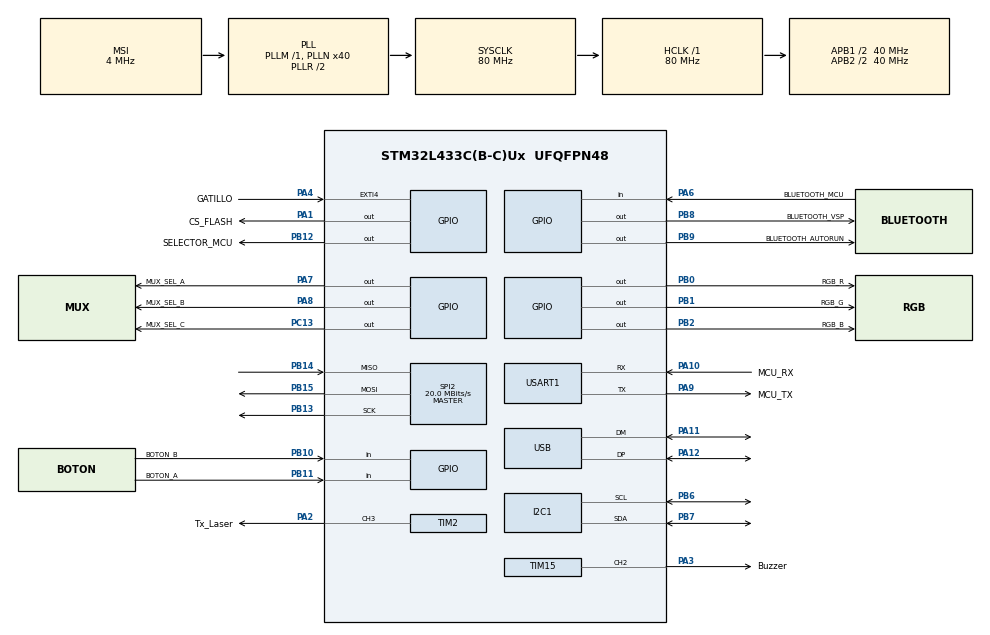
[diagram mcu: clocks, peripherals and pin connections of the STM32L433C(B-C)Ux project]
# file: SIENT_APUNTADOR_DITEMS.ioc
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FREERTOS.Tasks01=defaultTask,24,128,StartDefaultTask,Default,NULL,Dynamic,NULL,NULL
FREERTOS.configTOTAL_HEAP_SIZE=16384
FREERTOS.configUSE_NEWLIB_REENTRANT=1
FREERTOS.copyHeapFile=1
I2C1.CustomTiming=Disabled
I2C1.Timing=0x00D09BE3
Mcu.Family=STM32L4
Mcu.Name=STM32L433C(B-C)Ux
Mcu.Package=UFQFPN48
NVIC.EXTI4_IRQn=true\:5\:0\:false\:false\:true\:false\:true\:true\:true
NVIC.PriorityGroup=NVIC_PRIORITYGROUP_4
NVIC.TIM6_DAC_IRQn=true\:15\:0\:false\:false\:true\:false\:false\:true\:true
NVIC.TimeBase=TIM6_DAC_IRQn
NVIC.TimeBaseIP=TIM6
NVIC.USART1_IRQn=true\:5\:0\:true\:false\:true\:true\:true\:true\:true
NVIC.USB_IRQn=true\:5\:0\:false\:false\:true\:true\:false\:true\:true
PA1.GPIO_Label=CS_FLASH
PA1.Signal=GPIO_Output
PA10.GPIO_Label=MCU_RX
PA10.Mode=Asynchronous
PA10.Signal=USART1_RX
PA11.Mode=Device
PA11.Signal=USB_DM
PA12.Mode=Device
PA12.Signal=USB_DP
PA13\ (JTMS-SWDIO).Mode=Serial_Wire
PA13\ (JTMS-SWDIO).Signal=SYS_JTMS-SWDIO
PA14\ (JTCK-SWCLK).Mode=Serial_Wire
PA14\ (JTCK-SWCLK).Signal=SYS_JTCK-SWCLK
PA2.GPIO_Label=Tx_Laser
PA2.Signal=S_TIM2_CH3
PA3.GPIO_Label=Buzzer
PA3.Signal=S_TIM15_CH2
PA4.GPIO_Label=GATILLO
PA4.Signal=GPXTI4
PA6.GPIO_Label=BLUETOOTH_MCU
PA6.Signal=GPIO_Input
PA7.GPIO_Label=MUX_SEL_A
PA7.Signal=GPIO_Output
PA8.GPIO_Label=MUX_SEL_B
PA8.Signal=GPIO_Output
PA9.GPIO_Label=MCU_TX
PA9.Mode=Asynchronous
PA9.Signal=USART1_TX
PB0.GPIO_Label=RGB_R
PB0.Signal=GPIO_Output
PB1.GPIO_Label=RGB_G
PB1.Signal=GPIO_Output
PB10.GPIO_Label=BOTON_B
PB10.Signal=GPIO_Input
PB11.GPIO_Label=BOTON_A
PB11.Signal=GPIO_Input
PB12.GPIO_Label=SELECTOR_MCU
PB12.Signal=GPIO_Output
PB13.Mode=Full_Duplex_Master
PB13.Signal=SPI2_SCK
PB14.Mode=Full_Duplex_Master
PB14.Signal=SPI2_MISO
PB15.Mode=Full_Duplex_Master
PB15.Signal=SPI2_MOSI
PB2.GPIO_Label=RGB_B
PB2.Signal=GPIO_Output
PB6.Mode=I2C
PB6.Signal=I2C1_SCL
PB7.Mode=I2C
PB7.Signal=I2C1_SDA
PB8.GPIO_Label=BLUETOOTH_VSP
PB8.Signal=GPIO_Output
PB9.GPIO_Label=BLUETOOTH_AUTORUN
PB9.Signal=GPIO_Output
PC13.GPIO_Label=MUX_SEL_C
PC13.Signal=GPIO_Output
PC14-OSC32_IN\ (PC14).Mode=LSE-External-Oscillator
PC14-OSC32_IN\ (PC14).Signal=RCC_OSC32_IN
PC15-OSC32_OUT\ (PC15).Mode=LSE-External-Oscillator
PC15-OSC32_OUT\ (PC15).Signal=RCC_OSC32_OUT
ProjectManager.HeapSize=0x200
ProjectManager.StackSize=0x400
ProjectManager.TargetToolchain=STM32CubeIDE
RCC.ADCFreq_Value=48000000
RCC.AHBFreq_Value=80000000
RCC.APB1CLKDivider=RCC_HCLK_DIV2
RCC.APB1Freq_Value=40000000
RCC.APB1TimFreq_Value=80000000
RCC.APB2CLKDivider=RCC_HCLK_DIV2
RCC.APB2Freq_Value=40000000
RCC.APB2TimFreq_Value=80000000
RCC.CortexFreq_Value=80000000
RCC.HCLKFreq_Value=80000000
RCC.HSE_VALUE=8000000
RCC.HSI48_VALUE=48000000
RCC.HSI_VALUE=16000000
RCC.MSI_VALUE=4000000
RCC.PLLN=40
RCC.PLLSAI1N=24
RCC.SYSCLKFreq_VALUE=80000000
RCC.SYSCLKSource=RCC_SYSCLKSOURCE_PLLCLK
RCC.USBFreq_Value=48000000
RCC.VCOOutputFreq_Value=160000000
SH.S_TIM15_CH2.0=TIM15_CH2,PWM Generation2 CH2
SH.S_TIM2_CH3.0=TIM2_CH3,PWM Generation3 CH3
SPI2.CalculateBaudRate=20.0 MBits/s
SPI2.DataSize=SPI_DATASIZE_8BIT
SPI2.Direction=SPI_DIRECTION_2LINES
SPI2.Mode=SPI_MODE_MASTER
SPI2.VirtualType=VM_MASTER
TIM1.Prescaler=79
TIM15.Channel-PWM\ Generation2\ CH2=TIM_CHANNEL_2
TIM15.Prescaler=79
TIM2.Channel-PWM\ Generation3\ CH3=TIM_CHANNEL_3
TIM2.Period=24
TIM2.Prescaler=79
USART1.VirtualMode-Asynchronous=VM_ASYNC
USB_DEVICE.CLASS_NAME_FS=CDC
USB_DEVICE.VirtualMode=Cdc
USB_DEVICE.VirtualModeFS=Cdc_FS
VP_FREERTOS_VS_CMSIS_V2.Mode=CMSIS_V2
VP_SYS_VS_tim6.Mode=TIM6
VP_SYS_V_PVD_IN.Mode=Mode_PVD_Int
VP_TIM1_VS_ClockSourceINT.Mode=Internal
VP_TIM2_VS_ClockSourceINT.Mode=Internal
VP_USB_DEVICE_VS_USB_DEVICE_CDC_FS.Mode=CDC_FS
board=custom

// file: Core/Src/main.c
/* USER CODE BEGIN Header */
/**
  ******************************************************************************
  * @file           : main.c
  * @brief          : Main program body
  ******************************************************************************
  * @attention
  *
  * Copyright (c) 2026 STMicroelectronics.
  * All rights reserved.
  *
  * This software is licensed under terms that can be found in the LICENSE file
  * in the root directory of this software component.
  * If no LICENSE file comes with this software, it is provided AS-IS.
  *
  ******************************************************************************
  */
/* USER CODE END Header */
#include "main.h"
#include "cmsis_os.h"
#include "usb_device.h"

/* USER CODE BEGIN Includes */
#include "Inicializacion.h"
#include "Tareas_Interrupciones.h"
/* USER CODE END Includes */

I2C_HandleTypeDef hi2c1;

SPI_HandleTypeDef hspi2;

TIM_HandleTypeDef htim1;
TIM_HandleTypeDef htim2;
TIM_HandleTypeDef htim15;

UART_HandleTypeDef huart1;

/* Definitions for defaultTask */
osThreadId_t defaultTaskHandle;
const osThreadAttr_t defaultTask_attributes = {
  .name = "defaultTask",
  .stack_size = 128 * 4,
  .priority = (osPriority_t) osPriorityNormal,
};

void SystemClock_Config(void);
static void MX_GPIO_Init(void);
static void MX_I2C1_Init(void);
static void MX_SPI2_Init(void);
static void MX_USART1_UART_Init(void);
static void MX_TIM1_Init(void);
static void MX_TIM2_Init(void);
static void MX_TIM15_Init(void);
void StartDefaultTask(void *argument);

int main(void)
{

  /* MCU Configuration--------------------------------------------------------*/

  /* Reset of all peripherals, Initializes the Flash interface and the Systick. */
  HAL_Init();

  /* Configure the system clock */
  SystemClock_Config();

  /* Initialize all configured peripherals */
  MX_GPIO_Init();
  MX_I2C1_Init();
  MX_SPI2_Init();
  MX_USART1_UART_Init();
  MX_TIM1_Init();
  MX_TIM2_Init();
  MX_TIM15_Init();
  /* USER CODE BEGIN 2 */

  Inicializacion_Run();

  /* USER CODE END 2 */

  /* Init scheduler */
  osKernelInitialize();

  /* USER CODE BEGIN RTOS_MUTEX */
  Tareas_InicializarMutex();
  /* USER CODE END RTOS_MUTEX */

  /* Create the thread(s) */
  /* creation of defaultTask -- NO crear, no la usamos (ver Tareas_CrearTareas()).
   * CubeMX la reinserta sola en cada regeneracion -- volver a comentar esta
   * linea, o mejor, borrarla desde CubeMX (FreeRTOS -> Tasks and Queues). */
  /* defaultTaskHandle = osThreadNew(StartDefaultTask, NULL, &defaultTask_attributes); */

  /* USER CODE BEGIN RTOS_THREADS */
  Tareas_CrearTareas();
  /* USER CODE END RTOS_THREADS */

  /* Start scheduler */
  osKernelStart();

  /* We should never get here as control is now taken by the scheduler */

  /* Infinite loop */
  while (1)
  {

  }
}

void SystemClock_Config(void)
{
  RCC_OscInitTypeDef RCC_OscInitStruct = {0};
  RCC_ClkInitTypeDef RCC_ClkInitStruct = {0};

  /** Configure the main internal regulator output voltage
  */
  if (HAL_PWREx_ControlVoltageScaling(PWR_REGULATOR_VOLTAGE_SCALE1) != HAL_OK)
  {
    Error_Handler();
  }

  /** Configure LSE Drive Capability
  */
  HAL_PWR_EnableBkUpAccess();
  __HAL_RCC_LSEDRIVE_CONFIG(RCC_LSEDRIVE_LOW);

  /** Initializes the RCC Oscillators according to the specified parameters
  * in the RCC_OscInitTypeDef structure.
  */
  RCC_OscInitStruct.OscillatorType = RCC_OSCILLATORTYPE_LSE|RCC_OSCILLATORTYPE_MSI;
  RCC_OscInitStruct.LSEState = RCC_LSE_ON;
  RCC_OscInitStruct.MSIState = RCC_MSI_ON;
  RCC_OscInitStruct.MSICalibrationValue = 0;
  RCC_OscInitStruct.MSIClockRange = RCC_MSIRANGE_6;
  RCC_OscInitStruct.PLL.PLLState = RCC_PLL_ON;
  RCC_OscInitStruct.PLL.PLLSource = RCC_PLLSOURCE_MSI;
  RCC_OscInitStruct.PLL.PLLM = 1;
  RCC_OscInitStruct.PLL.PLLN = 40;
  RCC_OscInitStruct.PLL.PLLP = RCC_PLLP_DIV7;
  RCC_OscInitStruct.PLL.PLLQ = RCC_PLLQ_DIV2;
  RCC_OscInitStruct.PLL.PLLR = RCC_PLLR_DIV2;
  if (HAL_RCC_OscConfig(&RCC_OscInitStruct) != HAL_OK)
  {
    Error_Handler();
  }

  /** Initializes the CPU, AHB and APB buses clocks
  */
  RCC_ClkInitStruct.ClockType = RCC_CLOCKTYPE_HCLK|RCC_CLOCKTYPE_SYSCLK
                              |RCC_CLOCKTYPE_PCLK1|RCC_CLOCKTYPE_PCLK2;
  RCC_ClkInitStruct.SYSCLKSource = RCC_SYSCLKSOURCE_PLLCLK;
  RCC_ClkInitStruct.AHBCLKDivider = RCC_SYSCLK_DIV1;
  RCC_ClkInitStruct.APB1CLKDivider = RCC_HCLK_DIV2;
  RCC_ClkInitStruct.APB2CLKDivider = RCC_HCLK_DIV2;

  if (HAL_RCC_ClockConfig(&RCC_ClkInitStruct, FLASH_LATENCY_4) != HAL_OK)
  {
    Error_Handler();
  }

  /** Enable MSI Auto calibration
  */
  HAL_RCCEx_EnableMSIPLLMode();
}

static void MX_I2C1_Init(void)
{

  hi2c1.Instance = I2C1;
  hi2c1.Init.Timing = 0x00D09BE3;
  hi2c1.Init.OwnAddress1 = 0;
  hi2c1.Init.AddressingMode = I2C_ADDRESSINGMODE_7BIT;
  hi2c1.Init.DualAddressMode = I2C_DUALADDRESS_DISABLE;
  hi2c1.Init.OwnAddress2 = 0;
  hi2c1.Init.OwnAddress2Masks = I2C_OA2_NOMASK;
  hi2c1.Init.GeneralCallMode = I2C_GENERALCALL_DISABLE;
  hi2c1.Init.NoStretchMode = I2C_NOSTRETCH_DISABLE;
  if (HAL_I2C_Init(&hi2c1) != HAL_OK)
  {
    Error_Handler();
  }

  /** Configure Analogue filter
  */
  if (HAL_I2CEx_ConfigAnalogFilter(&hi2c1, I2C_ANALOGFILTER_ENABLE) != HAL_OK)
  {
    Error_Handler();
  }

  /** Configure Digital filter
  */
  if (HAL_I2CEx_ConfigDigitalFilter(&hi2c1, 0) != HAL_OK)
  {
    Error_Handler();
  }

}

static void MX_SPI2_Init(void)
{

  /* SPI2 parameter configuration*/
  hspi2.Instance = SPI2;
  hspi2.Init.Mode = SPI_MODE_MASTER;
  hspi2.Init.Direction = SPI_DIRECTION_2LINES;
  hspi2.Init.DataSize = SPI_DATASIZE_8BIT;
  hspi2.Init.CLKPolarity = SPI_POLARITY_LOW;
  hspi2.Init.CLKPhase = SPI_PHASE_1EDGE;
  hspi2.Init.NSS = SPI_NSS_SOFT;
  hspi2.Init.BaudRatePrescaler = SPI_BAUDRATEPRESCALER_2;
  hspi2.Init.FirstBit = SPI_FIRSTBIT_MSB;
  hspi2.Init.TIMode = SPI_TIMODE_DISABLE;
  hspi2.Init.CRCCalculation = SPI_CRCCALCULATION_DISABLE;
  hspi2.Init.CRCPolynomial = 7;
  hspi2.Init.CRCLength = SPI_CRC_LENGTH_DATASIZE;
  hspi2.Init.NSSPMode = SPI_NSS_PULSE_ENABLE;
  if (HAL_SPI_Init(&hspi2) != HAL_OK)
  {
    Error_Handler();
  }

}

static void MX_TIM1_Init(void)
{

  TIM_ClockConfigTypeDef sClockSourceConfig = {0};
  TIM_MasterConfigTypeDef sMasterConfig = {0};

  htim1.Instance = TIM1;
  htim1.Init.Prescaler = 79;
  htim1.Init.CounterMode = TIM_COUNTERMODE_UP;
  htim1.Init.Period = 65535;
  htim1.Init.ClockDivision = TIM_CLOCKDIVISION_DIV1;
  htim1.Init.RepetitionCounter = 0;
  htim1.Init.AutoReloadPreload = TIM_AUTORELOAD_PRELOAD_DISABLE;
  if (HAL_TIM_Base_Init(&htim1) != HAL_OK)
  {
    Error_Handler();
  }
  sClockSourceConfig.ClockSource = TIM_CLOCKSOURCE_INTERNAL;
  if (HAL_TIM_ConfigClockSource(&htim1, &sClockSourceConfig) != HAL_OK)
  {
    Error_Handler();
  }
  sMasterConfig.MasterOutputTrigger = TIM_TRGO_RESET;
  sMasterConfig.MasterOutputTrigger2 = TIM_TRGO2_RESET;
  sMasterConfig.MasterSlaveMode = TIM_MASTERSLAVEMODE_DISABLE;
  if (HAL_TIMEx_MasterConfigSynchronization(&htim1, &sMasterConfig) != HAL_OK)
  {
    Error_Handler();
  }

}

static void MX_TIM2_Init(void)
{

  TIM_ClockConfigTypeDef sClockSourceConfig = {0};
  TIM_MasterConfigTypeDef sMasterConfig = {0};
  TIM_OC_InitTypeDef sConfigOC = {0};

  htim2.Instance = TIM2;
  htim2.Init.Prescaler = 79;
  htim2.Init.CounterMode = TIM_COUNTERMODE_UP;
  htim2.Init.Period = 24;
  htim2.Init.ClockDivision = TIM_CLOCKDIVISION_DIV1;
  htim2.Init.AutoReloadPreload = TIM_AUTORELOAD_PRELOAD_DISABLE;
  if (HAL_TIM_Base_Init(&htim2) != HAL_OK)
  {
    Error_Handler();
  }
  sClockSourceConfig.ClockSource = TIM_CLOCKSOURCE_INTERNAL;
  if (HAL_TIM_ConfigClockSource(&htim2, &sClockSourceConfig) != HAL_OK)
  {
    Error_Handler();
  }
  if (HAL_TIM_PWM_Init(&htim2) != HAL_OK)
  {
    Error_Handler();
  }
  sMasterConfig.MasterOutputTrigger = TIM_TRGO_RESET;
  sMasterConfig.MasterSlaveMode = TIM_MASTERSLAVEMODE_DISABLE;
  if (HAL_TIMEx_MasterConfigSynchronization(&htim2, &sMasterConfig) != HAL_OK)
  {
    Error_Handler();
  }
  sConfigOC.OCMode = TIM_OCMODE_PWM1;
  sConfigOC.Pulse = 0;
  sConfigOC.OCPolarity = TIM_OCPOLARITY_HIGH;
  sConfigOC.OCFastMode = TIM_OCFAST_DISABLE;
  if (HAL_TIM_PWM_ConfigChannel(&htim2, &sConfigOC, TIM_CHANNEL_3) != HAL_OK)
  {
    Error_Handler();
  }
  HAL_TIM_MspPostInit(&htim2);

}

static void MX_TIM15_Init(void)
{

  TIM_MasterConfigTypeDef sMasterConfig = {0};
  TIM_OC_InitTypeDef sConfigOC = {0};
  TIM_BreakDeadTimeConfigTypeDef sBreakDeadTimeConfig = {0};

  htim15.Instance = TIM15;
  htim15.Init.Prescaler = 79;
  htim15.Init.CounterMode = TIM_COUNTERMODE_UP;
  htim15.Init.Period = 65535;
  htim15.Init.ClockDivision = TIM_CLOCKDIVISION_DIV1;
  htim15.Init.RepetitionCounter = 0;
  htim15.Init.AutoReloadPreload = TIM_AUTORELOAD_PRELOAD_DISABLE;
  if (HAL_TIM_PWM_Init(&htim15) != HAL_OK)
  {
    Error_Handler();
  }
  sMasterConfig.MasterOutputTrigger = TIM_TRGO_RESET;
  sMasterConfig.MasterSlaveMode = TIM_MASTERSLAVEMODE_DISABLE;
  if (HAL_TIMEx_MasterConfigSynchronization(&htim15, &sMasterConfig) != HAL_OK)
  {
    Error_Handler();
  }
  sConfigOC.OCMode = TIM_OCMODE_PWM1;
  sConfigOC.Pulse = 0;
  sConfigOC.OCPolarity = TIM_OCPOLARITY_HIGH;
  sConfigOC.OCNPolarity = TIM_OCNPOLARITY_HIGH;
  sConfigOC.OCFastMode = TIM_OCFAST_DISABLE;
  sConfigOC.OCIdleState = TIM_OCIDLESTATE_RESET;
  sConfigOC.OCNIdleState = TIM_OCNIDLESTATE_RESET;
  if (HAL_TIM_PWM_ConfigChannel(&htim15, &sConfigOC, TIM_CHANNEL_2) != HAL_OK)
  {
    Error_Handler();
  }
  sBreakDeadTimeConfig.OffStateRunMode = TIM_OSSR_DISABLE;
  sBreakDeadTimeConfig.OffStateIDLEMode = TIM_OSSI_DISABLE;
  sBreakDeadTimeConfig.LockLevel = TIM_LOCKLEVEL_OFF;
  sBreakDeadTimeConfig.DeadTime = 0;
  sBreakDeadTimeConfig.BreakState = TIM_BREAK_DISABLE;
  sBreakDeadTimeConfig.BreakPolarity = TIM_BREAKPOLARITY_HIGH;
  sBreakDeadTimeConfig.AutomaticOutput = TIM_AUTOMATICOUTPUT_DISABLE;
  if (HAL_TIMEx_ConfigBreakDeadTime(&htim15, &sBreakDeadTimeConfig) != HAL_OK)
  {
    Error_Handler();
  }
  HAL_TIM_MspPostInit(&htim15);

}

static void MX_USART1_UART_Init(void)
{

  huart1.Instance = USART1;
  huart1.Init.BaudRate = 115200;
  huart1.Init.WordLength = UART_WORDLENGTH_8B;
  huart1.Init.StopBits = UART_STOPBITS_1;
  huart1.Init.Parity = UART_PARITY_NONE;
  huart1.Init.Mode = UART_MODE_TX_RX;
  huart1.Init.HwFlowCtl = UART_HWCONTROL_NONE;
  huart1.Init.OverSampling = UART_OVERSAMPLING_16;
  huart1.Init.OneBitSampling = UART_ONE_BIT_SAMPLE_DISABLE;
  huart1.AdvancedInit.AdvFeatureInit = UART_ADVFEATURE_NO_INIT;
  if (HAL_UART_Init(&huart1) != HAL_OK)
  {
    Error_Handler();
  }

}

static void MX_GPIO_Init(void)
{
  GPIO_InitTypeDef GPIO_InitStruct = {0};

  /* GPIO Ports Clock Enable */
  __HAL_RCC_GPIOC_CLK_ENABLE();
  __HAL_RCC_GPIOA_CLK_ENABLE();
  __HAL_RCC_GPIOB_CLK_ENABLE();

  /*Configure GPIO pin Output Level */
  HAL_GPIO_WritePin(MUX_SEL_C_GPIO_Port, MUX_SEL_C_Pin, GPIO_PIN_RESET);

  /*Configure GPIO pin Output Level */
  HAL_GPIO_WritePin(GPIOA, CS_FLASH_Pin|MUX_SEL_A_Pin|MUX_SEL_B_Pin, GPIO_PIN_RESET);

  /*Configure GPIO pin Output Level */
  HAL_GPIO_WritePin(GPIOB, RGB_R_Pin|RGB_G_Pin|RGB_B_Pin|SELECTOR_MCU_Pin
                          |BLUETOOTH_VSP_Pin|BLUETOOTH_AUTORUN_Pin, GPIO_PIN_RESET);

  /*Configure GPIO pin : MUX_SEL_C_Pin */
  GPIO_InitStruct.Pin = MUX_SEL_C_Pin;
  GPIO_InitStruct.Mode = GPIO_MODE_OUTPUT_PP;
  GPIO_InitStruct.Pull = GPIO_NOPULL;
  GPIO_InitStruct.Speed = GPIO_SPEED_FREQ_LOW;
  HAL_GPIO_Init(MUX_SEL_C_GPIO_Port, &GPIO_InitStruct);

  /*Configure GPIO pins : CS_FLASH_Pin MUX_SEL_A_Pin MUX_SEL_B_Pin */
  GPIO_InitStruct.Pin = CS_FLASH_Pin|MUX_SEL_A_Pin|MUX_SEL_B_Pin;
  GPIO_InitStruct.Mode = GPIO_MODE_OUTPUT_PP;
  GPIO_InitStruct.Pull = GPIO_NOPULL;
  GPIO_InitStruct.Speed = GPIO_SPEED_FREQ_LOW;
  HAL_GPIO_Init(GPIOA, &GPIO_InitStruct);

  /*Configure GPIO pin : GATILLO_Pin */
  GPIO_InitStruct.Pin = GATILLO_Pin;
  GPIO_InitStruct.Mode = GPIO_MODE_IT_RISING;
  GPIO_InitStruct.Pull = GPIO_NOPULL;
  HAL_GPIO_Init(GATILLO_GPIO_Port, &GPIO_InitStruct);

  /*Configure GPIO pin : BLUETOOTH_MCU_Pin */
  GPIO_InitStruct.Pin = BLUETOOTH_MCU_Pin;
  GPIO_InitStruct.Mode = GPIO_MODE_INPUT;
  GPIO_InitStruct.Pull = GPIO_NOPULL;
  HAL_GPIO_Init(BLUETOOTH_MCU_GPIO_Port, &GPIO_InitStruct);

  /*Configure GPIO pins : RGB_R_Pin RGB_G_Pin RGB_B_Pin SELECTOR_MCU_Pin
                           BLUETOOTH_VSP_Pin BLUETOOTH_AUTORUN_Pin */
  GPIO_InitStruct.Pin = RGB_R_Pin|RGB_G_Pin|RGB_B_Pin|SELECTOR_MCU_Pin
                          |BLUETOOTH_VSP_Pin|BLUETOOTH_AUTORUN_Pin;
  GPIO_InitStruct.Mode = GPIO_MODE_OUTPUT_PP;
  GPIO_InitStruct.Pull = GPIO_NOPULL;
  GPIO_InitStruct.Speed = GPIO_SPEED_FREQ_LOW;
  HAL_GPIO_Init(GPIOB, &GPIO_InitStruct);

  /*Configure GPIO pins : BOTON_B_Pin BOTON_A_Pin */
  GPIO_InitStruct.Pin = BOTON_B_Pin|BOTON_A_Pin;
  GPIO_InitStruct.Mode = GPIO_MODE_INPUT;
  GPIO_InitStruct.Pull = GPIO_NOPULL;
  HAL_GPIO_Init(GPIOB, &GPIO_InitStruct);

  /* EXTI interrupt init*/
  HAL_NVIC_SetPriority(EXTI4_IRQn, 5, 0);
  HAL_NVIC_EnableIRQ(EXTI4_IRQn);

}

void StartDefaultTask(void *argument)
{
  /* init code for USB_DEVICE */
  /* MX_USB_DEVICE_Init(); -- NO llamar, ya se hizo en Inicializacion_Run()
   * (pre-RTOS); y de cualquier forma esta tarea ya no se crea arriba. */
  for(;;)
  {
    osDelay(1);
  }
}

void HAL_TIM_PeriodElapsedCallback(TIM_HandleTypeDef *htim)
{
  if (htim->Instance == TIM6)
  {
    HAL_IncTick();
  }
}

void Error_Handler(void)
{
  __disable_irq();
  while (1)
  {
  }
}
